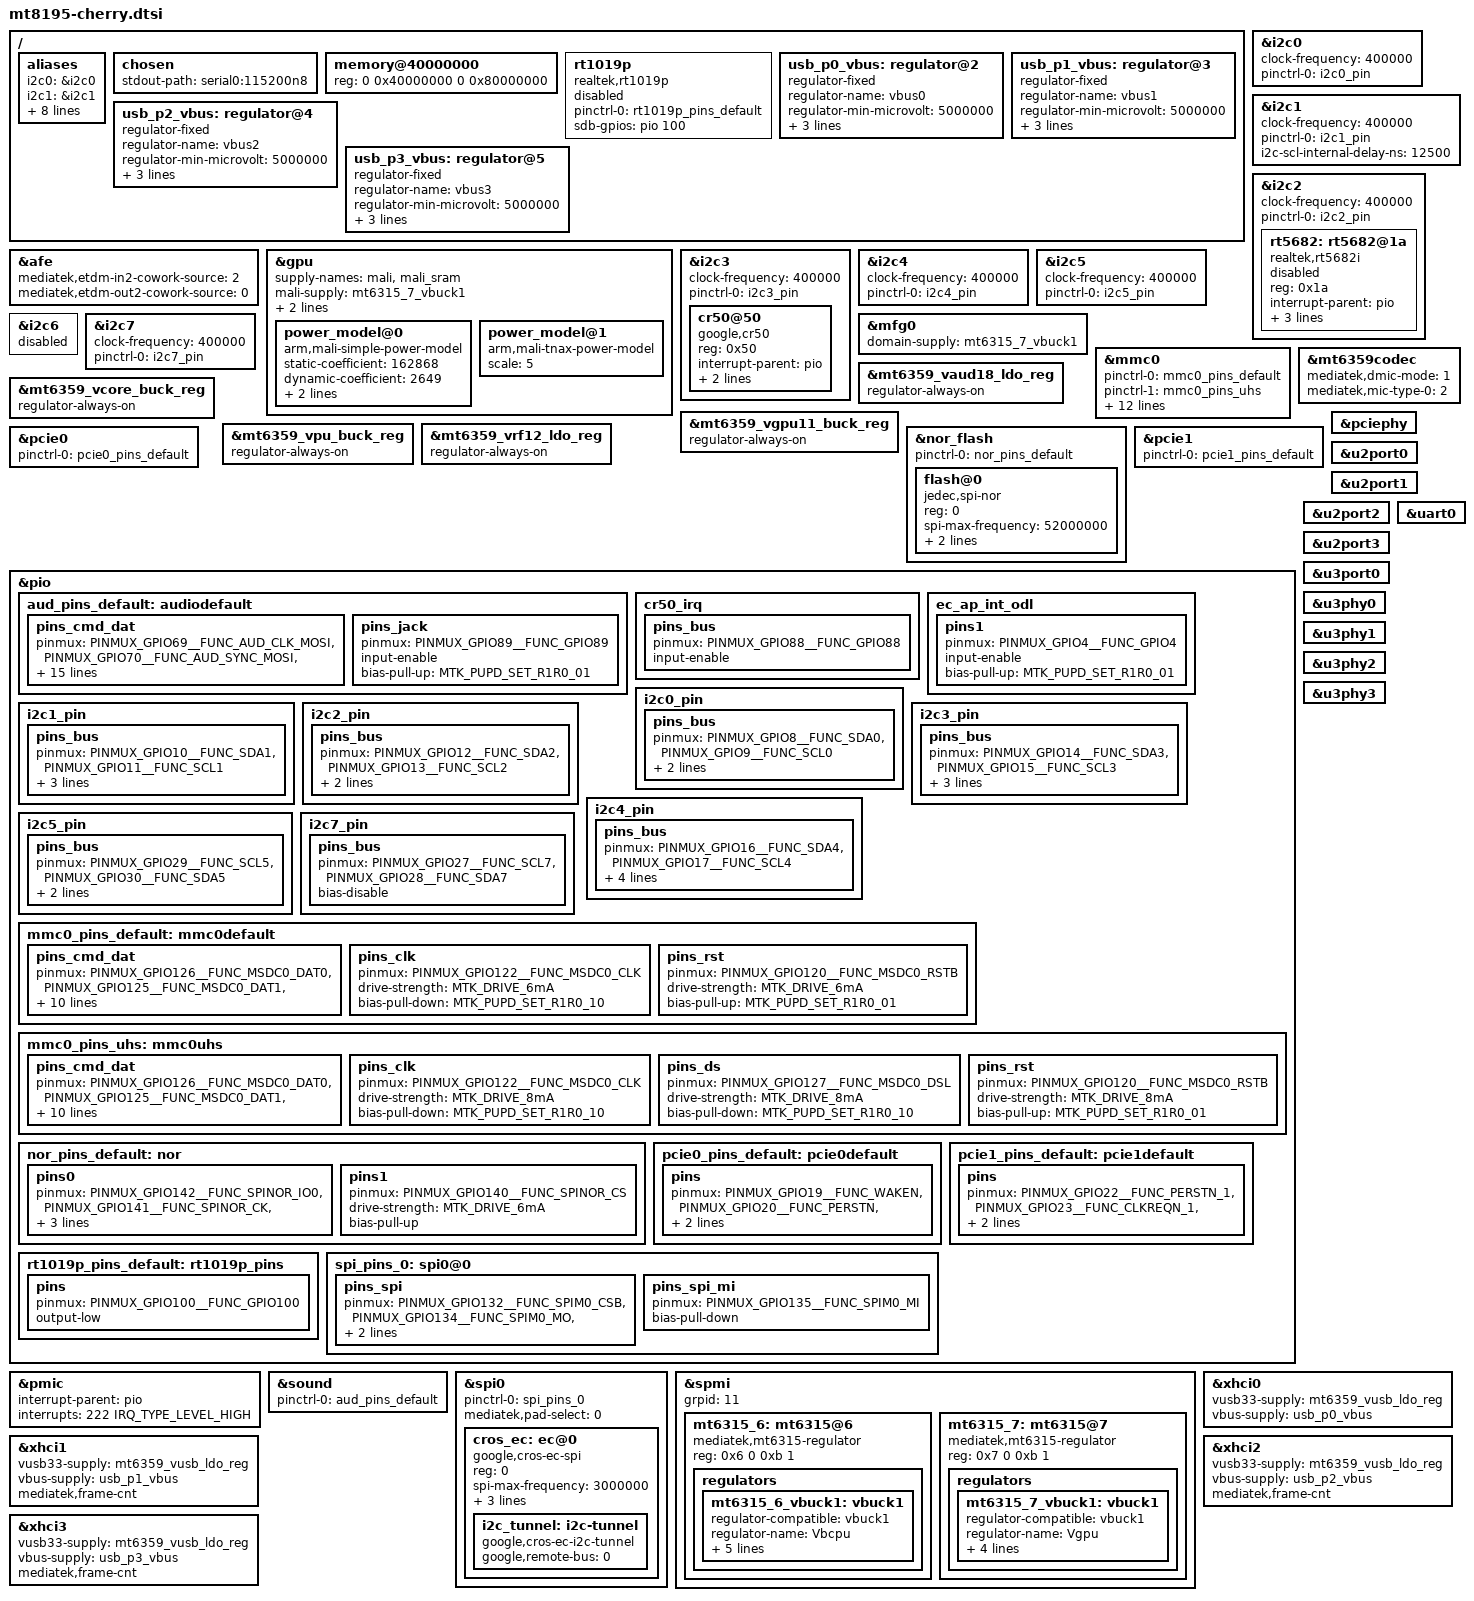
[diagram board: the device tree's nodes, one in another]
// SPDX-License-Identifier: (GPL-2.0 OR MIT)
/*
 * Copyright (C) 2021 MediaTek Inc.
 */
/dts-v1/;
#include <dt-bindings/gpio/gpio.h>
#include "mt8195.dtsi"
#include "mt6359.dtsi"

/ {
	aliases {
		i2c0 = &i2c0;
		i2c1 = &i2c1;
		i2c2 = &i2c2;
		i2c3 = &i2c3;
		i2c4 = &i2c4;
		i2c5 = &i2c5;
		i2c6 = &i2c6;
		i2c7 = &i2c7;
		mmc0 = &mmc0;
		serial0 = &uart0;
	};

	chosen {
		stdout-path = "serial0:115200n8";
	};

	memory@40000000 {
		device_type = "memory";
		reg = <0 0x40000000 0 0x80000000>;
	};

	rt1019p: rt1019p {
		compatible = "realtek,rt1019p";
		pinctrl-names = "default";
		pinctrl-0 = <&rt1019p_pins_default>;
		sdb-gpios = <&pio 100 GPIO_ACTIVE_HIGH>;
		status = "disabled";
	};


	usb_p0_vbus: regulator@2 {
		compatible = "regulator-fixed";
		regulator-name = "vbus0";
		regulator-min-microvolt = <5000000>;
		regulator-max-microvolt = <5000000>;
		enable-active-high;
		regulator-always-on;
	};

	usb_p1_vbus: regulator@3 {
		compatible = "regulator-fixed";
		regulator-name = "vbus1";
		regulator-min-microvolt = <5000000>;
		regulator-max-microvolt = <5000000>;
		enable-active-high;
		regulator-always-on;
	};

	usb_p2_vbus: regulator@4 {
		compatible = "regulator-fixed";
		regulator-name = "vbus2";
		regulator-min-microvolt = <5000000>;
		regulator-max-microvolt = <5000000>;
		enable-active-high;
		regulator-always-on;
	};

	usb_p3_vbus: regulator@5 {
		compatible = "regulator-fixed";
		regulator-name = "vbus3";
		regulator-min-microvolt = <5000000>;
		regulator-max-microvolt = <5000000>;
		enable-active-high;
		regulator-always-on;
	};
};

&afe {
	mediatek,etdm-in2-cowork-source = <2>;
	mediatek,etdm-out2-cowork-source = <0>;
	status = "okay";
};

&gpu {
	supply-names = "mali","mali_sram";
	mali-supply = <&mt6315_7_vbuck1>;
	mali_sram-supply = <&mt6359_vsram_others_ldo_reg>;
	operating-points-v2 = <&gpu_opp_table>;
	power_model@0 {
		compatible = "arm,mali-simple-power-model";
		static-coefficient = <162868>;
		dynamic-coefficient = <2649>;
		ts = <(-199560) 37873 (-665) 9>;
		thermal-zone = "soc_max";
	};
	power_model@1 {
		compatible = "arm,mali-tnax-power-model";
		scale = <5>;
	};
};

&i2c0 {
	status = "okay";
	clock-frequency = <400000>;
	pinctrl-names = "default";
	pinctrl-0 = <&i2c0_pin>;
};

&i2c1 {
	status = "okay";
	clock-frequency = <400000>;
	pinctrl-names = "default";
	pinctrl-0 = <&i2c1_pin>;
	i2c-scl-internal-delay-ns = <12500>;
};

&i2c2 {
	status = "okay";
	clock-frequency = <400000>;
	pinctrl-names = "default";
	pinctrl-0 = <&i2c2_pin>;

	rt5682: rt5682@1a {
               compatible = "realtek,rt5682i";
               reg = <0x1a>;
               interrupt-parent = <&pio>;
               interrupts = <89 IRQ_TYPE_EDGE_BOTH>;
               realtek,jd-src = <1>;
               realtek,btndet-delay = <16>;
               status = "disabled";
	};
};

&i2c3 {
	status = "okay";
	clock-frequency = <400000>;
	pinctrl-names = "default";
	pinctrl-0 = <&i2c3_pin>;

	cr50@50 {
		compatible = "google,cr50";
		reg = <0x50>;
		interrupt-parent = <&pio>;
		interrupts = <88 IRQ_TYPE_EDGE_FALLING>;
		pinctrl-names = "default";
		pinctrl-0 = <&cr50_irq>;
	};
};

&i2c4 {
	status = "okay";
	clock-frequency = <400000>;
	pinctrl-names = "default";
	pinctrl-0 = <&i2c4_pin>;
};

&i2c5 {
	status = "okay";
	clock-frequency = <400000>;
	pinctrl-names = "default";
	pinctrl-0 = <&i2c5_pin>;
};

&i2c6 {
	status = "disabled";
};

&i2c7 {
	status = "okay";
	clock-frequency = <400000>;
	pinctrl-names = "default";
	pinctrl-0 = <&i2c7_pin>;
};

&mfg0 {
	domain-supply = <&mt6315_7_vbuck1>;
};

&mmc0 {
	status = "okay";
	pinctrl-names = "default", "state_uhs";
	pinctrl-0 = <&mmc0_pins_default>;
	pinctrl-1 = <&mmc0_pins_uhs>;
	bus-width = <8>;
	max-frequency = <200000000>;
	cap-mmc-highspeed;
	mmc-hs200-1_8v;
	mmc-hs400-1_8v;
	cap-mmc-hw-reset;
	no-sdio;
	no-sd;
	hs400-ds-delay = <0x14c11>;
	vmmc-supply = <&mt6359_vemc_1_ldo_reg>;
	vqmmc-supply = <&mt6359_vufs_ldo_reg>;
	non-removable;
};

&mt6359_vaud18_ldo_reg {
	regulator-always-on;
};

/* for CPU-L */
&mt6359_vcore_buck_reg {
	regulator-always-on;
};

/* for CORE */
&mt6359_vgpu11_buck_reg {
	regulator-always-on;
};

/* for CORE SRAM */
&mt6359_vpu_buck_reg {
	regulator-always-on;
};

&mt6359_vrf12_ldo_reg {
	regulator-always-on;
};

&mt6359codec {
	mediatek,dmic-mode = <1>; /* one-wire */
	mediatek,mic-type-0 = <2>; /* DMIC */
};

&nor_flash {
	status = "okay";
	pinctrl-names = "default";
	pinctrl-0 = <&nor_pins_default>;

	flash@0 {
		compatible = "jedec,spi-nor";
		reg = <0>;
		spi-max-frequency = <52000000>;
		spi-rx-bus-width = <2>;
		spi-tx-bus-width = <2>;
	};
};

&pcie0 {
	pinctrl-names = "default";
	pinctrl-0 = <&pcie0_pins_default>;
	status = "okay";
};

&pcie1 {
	pinctrl-names = "default";
	pinctrl-0 = <&pcie1_pins_default>;
	status = "okay";
};

&pciephy {
	status = "okay";
};

&pio {
	aud_pins_default: audiodefault {
		pins_cmd_dat {
		    pinmux = <PINMUX_GPIO69__FUNC_AUD_CLK_MOSI>,
			     <PINMUX_GPIO70__FUNC_AUD_SYNC_MOSI>,
			     <PINMUX_GPIO71__FUNC_AUD_DAT_MOSI0>,
			     <PINMUX_GPIO72__FUNC_AUD_DAT_MOSI1>,
			     <PINMUX_GPIO73__FUNC_AUD_DAT_MISO0>,
			     <PINMUX_GPIO74__FUNC_AUD_DAT_MISO1>,
			     <PINMUX_GPIO75__FUNC_AUD_DAT_MISO2>,
			     <PINMUX_GPIO0__FUNC_TDMIN_MCK>,
			     <PINMUX_GPIO1__FUNC_TDMIN_DI>,
			     <PINMUX_GPIO2__FUNC_TDMIN_LRCK>,
			     <PINMUX_GPIO3__FUNC_TDMIN_BCK>,
			     <PINMUX_GPIO60__FUNC_I2SO2_D0>,
			     <PINMUX_GPIO49__FUNC_I2SIN_D0>,
			     <PINMUX_GPIO50__FUNC_I2SO1_MCK>,
			     <PINMUX_GPIO51__FUNC_I2SO1_BCK>,
			     <PINMUX_GPIO52__FUNC_I2SO1_WS>,
			     <PINMUX_GPIO53__FUNC_I2SO1_D0>;
		};

		pins_jack {
			pinmux = <PINMUX_GPIO89__FUNC_GPIO89>;
			input-enable;
			bias-pull-up = <MTK_PUPD_SET_R1R0_01>;
		};
	};

	cr50_irq: cr50_irq {
		pins_bus {
			pinmux = <PINMUX_GPIO88__FUNC_GPIO88>;
			input-enable;
		};
	};

	ec_ap_int_odl: ec_ap_int_odl {
		pins1 {
			pinmux = <PINMUX_GPIO4__FUNC_GPIO4>;
			input-enable;
			bias-pull-up = <MTK_PUPD_SET_R1R0_01>;
		};
	};

	i2c0_pin: i2c0_pin {
		pins_bus {
			pinmux = <PINMUX_GPIO8__FUNC_SDA0>,
				 <PINMUX_GPIO9__FUNC_SCL0>;
			bias-disable;
			mediatek,drive-strength-adv = <7>;
		};
	};

	i2c1_pin: i2c1_pin {
		pins_bus {
			pinmux = <PINMUX_GPIO10__FUNC_SDA1>,
				 <PINMUX_GPIO11__FUNC_SCL1>;
			bias-pull-up;
			mediatek,rsel = <7>;
			mediatek,drive-strength-adv = <7>;
		};
	};

	i2c2_pin: i2c2_pin {
		pins_bus {
			pinmux = <PINMUX_GPIO12__FUNC_SDA2>,
				 <PINMUX_GPIO13__FUNC_SCL2>;
			bias-disable;
			mediatek,drive-strength-adv = <7>;
		};
	};

	i2c3_pin: i2c3_pin {
		pins_bus {
			pinmux = <PINMUX_GPIO14__FUNC_SDA3>,
				 <PINMUX_GPIO15__FUNC_SCL3>;
			bias-pull-up;
			mediatek,rsel = <7>;
			mediatek,drive-strength-adv = <7>;
		};
	};

	i2c4_pin: i2c4_pin {
		pins_bus {
			pinmux = <PINMUX_GPIO16__FUNC_SDA4>,
				 <PINMUX_GPIO17__FUNC_SCL4>;
			bias-pull-up;
			mediatek,rsel = <7>;
			mediatek,drive-strength-adv = <0>;
			drive-strength = <MTK_DRIVE_4mA>;
		};
	};

	i2c5_pin: i2c5_pin {
		pins_bus {
			pinmux = <PINMUX_GPIO29__FUNC_SCL5>,
				 <PINMUX_GPIO30__FUNC_SDA5>;
			bias-disable;
			mediatek,drive-strength-adv = <7>;
		};
	};

	i2c7_pin: i2c7_pin {
		pins_bus {
			pinmux = <PINMUX_GPIO27__FUNC_SCL7>,
				 <PINMUX_GPIO28__FUNC_SDA7>;
			bias-disable;
		};
	};

	mmc0_pins_default: mmc0default {
		pins_cmd_dat {
			pinmux = <PINMUX_GPIO126__FUNC_MSDC0_DAT0>,
				 <PINMUX_GPIO125__FUNC_MSDC0_DAT1>,
				 <PINMUX_GPIO124__FUNC_MSDC0_DAT2>,
				 <PINMUX_GPIO123__FUNC_MSDC0_DAT3>,
				 <PINMUX_GPIO119__FUNC_MSDC0_DAT4>,
				 <PINMUX_GPIO118__FUNC_MSDC0_DAT5>,
				 <PINMUX_GPIO117__FUNC_MSDC0_DAT6>,
				 <PINMUX_GPIO116__FUNC_MSDC0_DAT7>,
				 <PINMUX_GPIO121__FUNC_MSDC0_CMD>;
			input-enable;
			drive-strength = <MTK_DRIVE_6mA>;
			bias-pull-up = <MTK_PUPD_SET_R1R0_01>;
		};

		pins_clk {
			pinmux = <PINMUX_GPIO122__FUNC_MSDC0_CLK>;
			drive-strength = <MTK_DRIVE_6mA>;
			bias-pull-down = <MTK_PUPD_SET_R1R0_10>;
		};

		pins_rst {
			pinmux = <PINMUX_GPIO120__FUNC_MSDC0_RSTB>;
			drive-strength = <MTK_DRIVE_6mA>;
			bias-pull-up = <MTK_PUPD_SET_R1R0_01>;
		};
	};

	mmc0_pins_uhs: mmc0uhs{
		pins_cmd_dat {
			pinmux = <PINMUX_GPIO126__FUNC_MSDC0_DAT0>,
				 <PINMUX_GPIO125__FUNC_MSDC0_DAT1>,
				 <PINMUX_GPIO124__FUNC_MSDC0_DAT2>,
				 <PINMUX_GPIO123__FUNC_MSDC0_DAT3>,
				 <PINMUX_GPIO119__FUNC_MSDC0_DAT4>,
				 <PINMUX_GPIO118__FUNC_MSDC0_DAT5>,
				 <PINMUX_GPIO117__FUNC_MSDC0_DAT6>,
				 <PINMUX_GPIO116__FUNC_MSDC0_DAT7>,
				 <PINMUX_GPIO121__FUNC_MSDC0_CMD>;
			input-enable;
			drive-strength = <MTK_DRIVE_8mA>;
			bias-pull-up = <MTK_PUPD_SET_R1R0_01>;
		};

		pins_clk {
			pinmux = <PINMUX_GPIO122__FUNC_MSDC0_CLK>;
			drive-strength = <MTK_DRIVE_8mA>;
			bias-pull-down = <MTK_PUPD_SET_R1R0_10>;
		};

		pins_ds {
			pinmux = <PINMUX_GPIO127__FUNC_MSDC0_DSL>;
			drive-strength = <MTK_DRIVE_8mA>;
			bias-pull-down = <MTK_PUPD_SET_R1R0_10>;
		};

		pins_rst {
			pinmux = <PINMUX_GPIO120__FUNC_MSDC0_RSTB>;
			drive-strength = <MTK_DRIVE_8mA>;
			bias-pull-up = <MTK_PUPD_SET_R1R0_01>;
		};
	};

	nor_pins_default: nor {
		pins0 {
			pinmux = <PINMUX_GPIO142__FUNC_SPINOR_IO0>,
				 <PINMUX_GPIO141__FUNC_SPINOR_CK>,
				 <PINMUX_GPIO143__FUNC_SPINOR_IO1>;
			drive-strength = <MTK_DRIVE_6mA>;
			bias-pull-down;
		};

		pins1 {
			pinmux = <PINMUX_GPIO140__FUNC_SPINOR_CS>;
			drive-strength = <MTK_DRIVE_6mA>;
			bias-pull-up;
		};
	};

	pcie0_pins_default: pcie0default {
		pins {
			pinmux = <PINMUX_GPIO19__FUNC_WAKEN>,
				 <PINMUX_GPIO20__FUNC_PERSTN>,
				 <PINMUX_GPIO21__FUNC_CLKREQN>;
				 bias-pull-up;
		};
	};

	pcie1_pins_default: pcie1default {
		pins {
			pinmux = <PINMUX_GPIO22__FUNC_PERSTN_1>,
				 <PINMUX_GPIO23__FUNC_CLKREQN_1>,
				 <PINMUX_GPIO24__FUNC_WAKEN_1>;
				 bias-pull-up;
		};
	};

	rt1019p_pins_default: rt1019p_pins {
		pins {
			pinmux = <PINMUX_GPIO100__FUNC_GPIO100>;
			output-low;
		};
	};

	spi_pins_0: spi0@0 {
		pins_spi {
			pinmux = <PINMUX_GPIO132__FUNC_SPIM0_CSB>,
				 <PINMUX_GPIO134__FUNC_SPIM0_MO>,
				 <PINMUX_GPIO133__FUNC_SPIM0_CLK>;
			bias-disable;
		};
		pins_spi_mi {
			pinmux = <PINMUX_GPIO135__FUNC_SPIM0_MI>;
			bias-pull-down;
		};
	};
};

&pmic {
	interrupt-parent = <&pio>;
	interrupts = <222 IRQ_TYPE_LEVEL_HIGH>;
};

&sound {
	pinctrl-names = "default";
	pinctrl-0 = <&aud_pins_default>;
	status = "okay";
};

&spi0 {
	pinctrl-names = "default";
	pinctrl-0 = <&spi_pins_0>;
	mediatek,pad-select = <0>;
	status = "okay";

	cros_ec: ec@0 {
		compatible = "google,cros-ec-spi";
		reg = <0>;
		spi-max-frequency = <3000000>;
		interrupt-parent = <&pio>;
		interrupts = <4 IRQ_TYPE_LEVEL_LOW>;
		pinctrl-names = "default";
		pinctrl-0 = <&ec_ap_int_odl>;

		#address-cells = <1>;
		#size-cells = <0>;

		i2c_tunnel: i2c-tunnel {
			compatible = "google,cros-ec-i2c-tunnel";
			google,remote-bus = <0>;
			#address-cells = <1>;
			#size-cells = <0>;
		};
	};
};

&spmi {
	grpid = <11>;
	mt6315_6: mt6315@6 {
		compatible = "mediatek,mt6315-regulator";
		reg = <0x6 0 0xb 1>;

		regulators {
			mt6315_6_vbuck1: vbuck1 {
				regulator-compatible = "vbuck1";
				regulator-name = "Vbcpu";
				regulator-min-microvolt = <300000>;
				regulator-max-microvolt = <1193750>;
				regulator-enable-ramp-delay = <256>;
				regulator-allowed-modes = <0 1 2 4>;
				regulator-always-on;
			};
		};
	};

	mt6315_7: mt6315@7 {
		compatible = "mediatek,mt6315-regulator";
		reg = <0x7 0 0xb 1>;

		regulators {
			mt6315_7_vbuck1: vbuck1 {
				regulator-compatible = "vbuck1";
				regulator-name = "Vgpu";
				regulator-min-microvolt = <300000>;
				regulator-max-microvolt = <1193750>;
				regulator-enable-ramp-delay = <256>;
				regulator-allowed-modes = <0 1 2 4>;
			};
		};
	};
};

&u2port0 {
	status = "okay";
};

&u2port1 {
	status = "okay";
};

&u2port2 {
	status = "okay";
};

&u2port3 {
	status = "okay";
};

&u3port0 {
	status = "okay";
};

&u3phy0 {
	status="okay";
};

&u3phy1 {
	status = "okay";
};

&u3phy2 {
	status="okay";
};

&u3phy3 {
	status="okay";
};

&uart0 {
	status = "okay";
};

&xhci0 {
	vusb33-supply = <&mt6359_vusb_ldo_reg>;
	vbus-supply = <&usb_p0_vbus>;
	status = "okay";
};

&xhci1 {
	vusb33-supply = <&mt6359_vusb_ldo_reg>;
	vbus-supply = <&usb_p1_vbus>;
	mediatek,frame-cnt;
	status = "okay";
};

&xhci2 {
	vusb33-supply = <&mt6359_vusb_ldo_reg>;
	vbus-supply = <&usb_p2_vbus>;
	mediatek,frame-cnt;
	status = "okay";
};

&xhci3 {
	vusb33-supply = <&mt6359_vusb_ldo_reg>;
	vbus-supply = <&usb_p3_vbus>;
	mediatek,frame-cnt;
	status = "okay";
};
